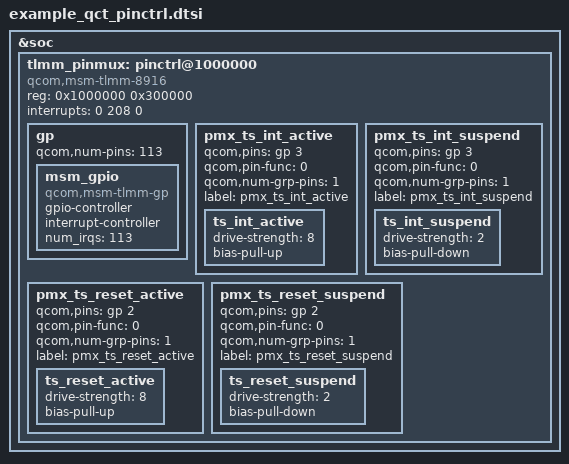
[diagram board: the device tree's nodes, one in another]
//touch-related part only

&soc {
	//...
	
	tlmm_pinmux: pinctrl@1000000 {
		compatible = "qcom,msm-tlmm-8916";
		reg = <0x1000000 0x300000>;
		interrupts = <0 208 0>;

		/*General purpose pins*/
		gp: gp {
			qcom,num-pins = <113>;
			#qcom,pin-cells = <1>;
			msm_gpio: msm_gpio {
				compatible = "qcom,msm-tlmm-gp";
				gpio-controller;
				#gpio-cells = <2>;
				interrupt-controller;
				#interrupt-cells = <2>;
				num_irqs = <113>;
			};
		};
		//...

		pmx_ts_int_active {
			qcom,pins = <&gp 3>;
			qcom,pin-func = <0>;
			qcom,num-grp-pins = <1>;
			label = "pmx_ts_int_active";

			ts_int_active: ts_int_active {
				drive-strength = <8>;
				bias-pull-up;
			};
		};

		pmx_ts_int_suspend {
			qcom,pins = <&gp 3>;
			qcom,pin-func = <0>;
			qcom,num-grp-pins = <1>;
			label = "pmx_ts_int_suspend";

			ts_int_suspend: ts_int_suspend {
				drive-strength = <2>;
				bias-pull-down;
			};
		};

		pmx_ts_reset_active {
			qcom,pins = <&gp 2>;
			qcom,pin-func = <0>;
			qcom,num-grp-pins = <1>;
			label = "pmx_ts_reset_active";

			ts_reset_active: ts_reset_active {
				drive-strength = <8>;
				bias-pull-up;
			};
		};

		pmx_ts_reset_suspend {
			qcom,pins = <&gp 2>;
			qcom,pin-func = <0>;
			qcom,num-grp-pins = <1>;
			label = "pmx_ts_reset_suspend";

			ts_reset_suspend: ts_reset_suspend {
				drive-strength = <2>;
				bias-pull-down;
			};
		};
		//...
	};
	//...
};

